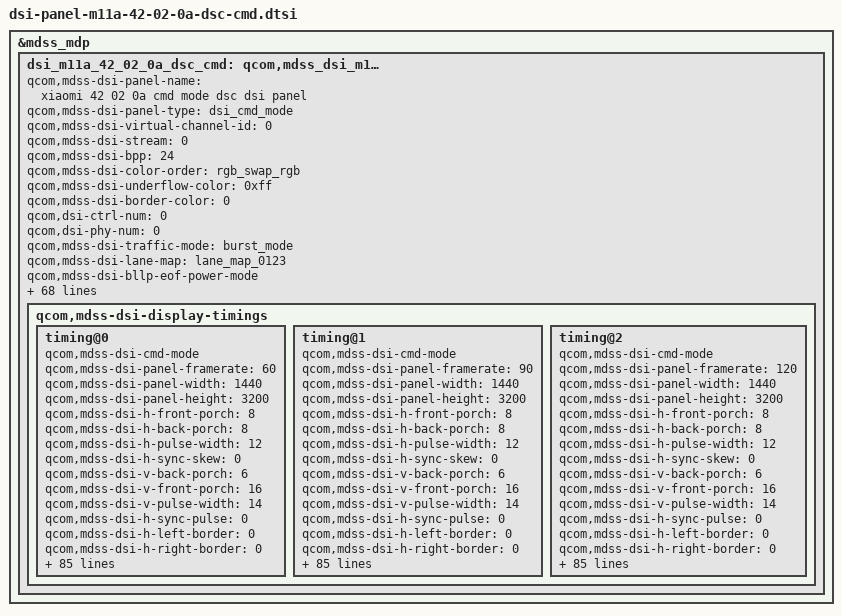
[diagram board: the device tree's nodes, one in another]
&mdss_mdp {
	dsi_m11a_42_02_0a_dsc_cmd: qcom,mdss_dsi_m11a_42_02_0a_dsc_cmd {
		qcom,mdss-dsi-panel-name = "xiaomi 42 02 0a cmd mode dsc dsi panel";
		qcom,mdss-dsi-panel-type = "dsi_cmd_mode";
		qcom,mdss-dsi-virtual-channel-id = <0>;
		qcom,mdss-dsi-stream = <0>;
		qcom,mdss-dsi-bpp = <24>;
		qcom,mdss-dsi-color-order = "rgb_swap_rgb";
		qcom,mdss-dsi-underflow-color = <0xff>;
		qcom,mdss-dsi-border-color = <0>;
		qcom,dsi-ctrl-num = <0>;
		qcom,dsi-phy-num = <0>;

		qcom,mdss-dsi-traffic-mode = "burst_mode";
		qcom,mdss-dsi-lane-map = "lane_map_0123";
		qcom,mdss-dsi-bllp-eof-power-mode;
		qcom,mdss-dsi-bllp-power-mode;
		qcom,mdss-dsi-lane-0-state;
		qcom,mdss-dsi-lane-1-state;
		qcom,mdss-dsi-lane-2-state;
		qcom,mdss-dsi-lane-3-state;
		qcom,mdss-dsi-dma-trigger = "trigger_sw";
		qcom,mdss-dsi-mdp-trigger = "none";
		qcom,mdss-dsi-reset-sequence = <1 11>, <0 1>, <1 11>;
		qcom,mdss-pan-physical-width-dimension = <701>;
		qcom,mdss-pan-physical-height-dimension = <1558>;
		qcom,mdss-dsi-te-pin-select = <1>;
		qcom,mdss-dsi-wr-mem-start = <0x2c>;
		qcom,mdss-dsi-wr-mem-continue = <0x3c>;
		qcom,mdss-dsi-te-dcs-command = <1>;
		qcom,mdss-dsi-te-check-enable;
		qcom,mdss-dsi-te-using-te-pin;
		qcom,mdss-dsi-tx-eot-append;
		qcom,mdss-dsi-lp11-init;

		qcom,mdss-dsi-bl-inverted-dbv;
		qcom,bl-update-flag = "delay_until_first_frame";

		qcom,mdss-dsi-panel-hdr-enabled;
		qcom,mdss-dsi-panel-hdr-color-primaries = <14500 15500 32000
			17000 15500 30000 8000 3000>;
		qcom,mdss-dsi-panel-peak-brightness = <4200000>;
		qcom,mdss-dsi-panel-blackness-level = <3230>;

		qcom,mdss-dsi-dma-schedule-line = <1>;
		qcom,mdss-dsi-dma-schedule-window = <50>;

		qcom,mdss-dsi-display-timings {
			/* 60 Hz */
			timing@0 {
				qcom,mdss-dsi-cmd-mode;
				qcom,mdss-dsi-panel-framerate = <60>;
				qcom,mdss-dsi-panel-width = <1440>;
				qcom,mdss-dsi-panel-height = <3200>;
				qcom,mdss-dsi-h-front-porch = <8>;
				qcom,mdss-dsi-h-back-porch = <8>;
				qcom,mdss-dsi-h-pulse-width = <12>;
				qcom,mdss-dsi-h-sync-skew = <0>;
				qcom,mdss-dsi-v-back-porch = <6>;
				qcom,mdss-dsi-v-front-porch = <16>;
				qcom,mdss-dsi-v-pulse-width = <14>;
				qcom,mdss-dsi-h-sync-pulse = <0>;
				qcom,mdss-dsi-h-left-border = <0>;
				qcom,mdss-dsi-h-right-border = <0>;
				qcom,mdss-dsi-v-top-border = <0>;
				qcom,mdss-dsi-v-bottom-border = <0>;
				qcom,mdss-dsi-panel-clockrate = <1200000000>;
				qcom,mdss-dsi-panel-jitter = <0x5 0x1>;
				qcom,mdss-mdp-transfer-time-us = <7300>;
				qcom,mdss-dsi-on-command = [
					/* swire advance 1 frame */
					39 00 00 00 00 00 06 F0 55 AA 52 08 01
					15 00 00 00 00 00 02 6F 02
					15 00 00 00 00 00 02 D2 2A
					/* DVDD strong */
					39 00 00 00 00 00 06 F0 55 AA 52 08 01
					15 00 00 00 00 00 02 6F 01
					39 00 00 00 00 00 04 C5 0B 0B 0B
					39 00 00 00 00 00 06 F0 55 AA 52 08 04
					15 00 00 00 00 00 02 C0 20
					/* Source Rising/Falling Time Strong */
					39 00 00 00 00 00 06 F0 55 AA 52 08 00
					15 00 00 00 00 00 02 6F 20
					39 00 00 00 00 00 09 C6 55 55 55 55 55 55 55 55
					39 00 00 00 00 00 05 FF AA 55 A5 80
					15 00 00 00 00 00 02 6F 1B
					15 00 00 00 00 00 02 F4 55
					15 00 00 00 00 00 02 6F 19
					15 00 00 00 00 00 02 F2 00
					39 00 00 00 00 00 05 FF AA 55 A5 81
					15 00 00 00 00 00 02 6F 18
					15 00 00 00 00 00 02 FB 04
					39 00 00 00 00 00 05 FF AA 55 A5 81
					15 00 00 00 00 00 02 6F 07
					15 00 00 00 00 00 02 FC 08
					/* CASET/RASET Setting 1440*3200 */
					39 00 00 00 00 00 05 2A 00 00 05 9F
					39 00 00 00 00 00 05 2B 00 00 0C 7F
					/* DSC Setting */
					15 00 00 00 00 00 02 90 03
					39 00 00 00 00 00 13 91
						AB A8 00 20 D2 00 02 86 03 5E 00 0A 03 5B 02 63
						10 F0
					/* TE ON */
					15 00 00 00 00 00 02 35 00
					15 00 00 00 00 00 02 5A 01
					/* Backlight On */
					39 00 00 00 00 00 05 3B 00 18 00 10
					15 00 00 00 00 00 02 53 20
					39 00 00 00 00 00 07 51 00 00 0F FF 0F FF
					15 00 00 00 00 00 02 9C 01
					15 00 00 00 00 00 02 2C 00
					/* 60Hz GIR off */
					15 00 00 00 00 00 02 2F 02
					15 00 00 40 00 00 02 5F 01
					15 00 00 40 00 00 02 26 00
					15 00 00 40 00 00 02 8B 00
					39 00 00 40 00 00 06 F0 55 AA 52 08 00
					15 00 00 40 00 00 02 6F 03
					15 00 00 40 00 00 02 C0 10
					15 00 00 40 00 00 02 6F 31
					15 00 00 40 00 00 02 DF 21
					39 00 00 40 00 00 06 F0 55 AA 52 08 02
					15 00 00 40 00 00 02 CC 30
					15 00 00 40 14 00 02 CE 01
					15 00 00 00 00 00 02 CC 00
					/* ESD Error Flag, Normal High, Error Low */
					39 00 00 40 00 00 06 F0 55 AA 52 08 00
					15 00 00 40 00 00 02 6F 05
					15 00 00 00 00 00 02 BE 88
					/* dimming step timing */
					39 00 00 40 00 00 06 F0 55 AA 52 08 00
					15 00 00 40 00 00 02 B2 09
					15 00 00 40 00 00 02 6F 05
					39 00 00 00 00 00 03 B2 08 08
					/* round on */
					39 00 00 00 00 00 06 F0 55 AA 52 08 07
					15 00 00 00 00 00 02 C0 B1
					/* Sleep Out */
					05 00 00 00 78 00 02 11 00
					/* Display On */
					05 00 00 00 00 00 02 29 00
				];
				qcom,mdss-dsi-off-command = [
					39 00 00 00 14 00 02 28 00
					39 00 00 00 64 00 02 10 00
				];
				qcom,mdss-dsi-on-command-state = "dsi_lp_mode";
				qcom,mdss-dsi-off-command-state = "dsi_lp_mode";

				qcom,mdss-dsi-timing-switch-command = [
					/* 60Hz */
					15 00 00 00 00 00 02 2F 02
					15 00 00 40 00 00 02 8B 00
					39 00 00 40 00 00 06 F0 55 AA 52 08 00
					15 00 00 40 00 00 02 6F 03
					15 00 00 40 00 00 02 C0 10
					15 00 00 40 00 00 02 6F 31
					15 00 00 40 00 00 02 DF 21
					39 00 00 40 00 00 06 F0 55 AA 52 08 02
					15 00 00 40 00 00 02 CC 30
					15 00 00 00 14 00 02 CE 01
					15 00 00 00 00 00 02 CC 00
				];

				qcom,mdss-dsi-timing-switch-command-update = <0xC0 4 1>, <0xDF 6 1>;
				qcom,mdss-dsi-timing-switch-command-state = "dsi_hs_mode";

				qcom,mdss-dsi-nolp-command = [
					39 00 00 40 00 00 03 51 00 00
					39 00 00 40 00 00 06 F0 55 AA 52 08 01
					15 00 00 40 00 00 02 6F 02
					15 00 00 40 00 00 02 B0 08
					15 00 00 40 00 00 02 E4 80
					15 00 00 40 00 00 02 6F 0A
					15 00 00 40 00 00 02 E4 80
					15 00 00 40 00 00 02 65 00
					05 00 00 00 00 00 01 38
					/* restore 60hz GIR off*/
					15 00 00 40 00 00 02 2F 02
					15 00 00 40 00 00 02 5F 01
					15 00 00 40 00 00 02 26 00
					15 00 00 40 00 00 02 8B 00
					39 00 00 40 00 00 06 F0 55 AA 52 08 00
					15 00 00 40 00 00 02 6F 03
					15 00 00 40 00 00 02 C0 10
					15 00 00 40 00 00 02 6F 31
					15 00 00 40 00 00 02 DF 20
					39 00 00 40 00 00 06 F0 55 AA 52 08 02
					15 00 00 40 00 00 02 CC 30
					15 00 00 00 14 00 02 CE 01
					15 00 00 00 00 00 02 CC 00
				];
				qcom,mdss-dsi-nolp-command-state = "dsi_hs_mode";

				qcom,compression-mode = "dsc";
				qcom,mdss-dsc-version = <0x12>;
				qcom,mdss-dsc-scr-version = <0x0>;
				qcom,mdss-dsc-slice-height = <32>;
				qcom,mdss-dsc-slice-width = <720>;
				qcom,mdss-dsc-slice-per-pkt = <2>;
				qcom,mdss-dsc-bit-per-component = <10>;
				qcom,mdss-dsc-bit-per-pixel = <8>;
				qcom,mdss-dsc-block-prediction-enable;
			};

			/* 90 Hz */
			timing@1 {
				qcom,mdss-dsi-cmd-mode;
				qcom,mdss-dsi-panel-framerate = <90>;
				qcom,mdss-dsi-panel-width = <1440>;
				qcom,mdss-dsi-panel-height = <3200>;
				qcom,mdss-dsi-h-front-porch = <8>;
				qcom,mdss-dsi-h-back-porch = <8>;
				qcom,mdss-dsi-h-pulse-width = <12>;
				qcom,mdss-dsi-h-sync-skew = <0>;
				qcom,mdss-dsi-v-back-porch = <6>;
				qcom,mdss-dsi-v-front-porch = <16>;
				qcom,mdss-dsi-v-pulse-width = <14>;
				qcom,mdss-dsi-h-sync-pulse = <0>;
				qcom,mdss-dsi-h-left-border = <0>;
				qcom,mdss-dsi-h-right-border = <0>;
				qcom,mdss-dsi-v-top-border = <0>;
				qcom,mdss-dsi-v-bottom-border = <0>;
				qcom,mdss-dsi-panel-clockrate = <1200000000>;
				qcom,mdss-dsi-panel-jitter = <0x5 0x1>;
				qcom,mdss-mdp-transfer-time-us = <7300>;
				qcom,mdss-dsi-on-command = [
					/* swire advance 1 frame */
					39 00 00 00 00 00 06 F0 55 AA 52 08 01
					15 00 00 00 00 00 02 6F 02
					15 00 00 00 00 00 02 D2 2A
					/* DVDD strong */
					39 00 00 00 00 00 06 F0 55 AA 52 08 01
					15 00 00 00 00 00 02 6F 01
					39 00 00 00 00 00 04 C5 0B 0B 0B
					39 00 00 00 00 00 06 F0 55 AA 52 08 04
					15 00 00 00 00 00 02 C0 20
					/* Source Rising/Falling Time Strong */
					39 00 00 00 00 00 06 F0 55 AA 52 08 00
					15 00 00 00 00 00 02 6F 20
					39 00 00 00 00 00 09 C6 55 55 55 55 55 55 55 55
					39 00 00 00 00 00 05 FF AA 55 A5 80
					15 00 00 00 00 00 02 6F 1B
					15 00 00 00 00 00 02 F4 55
					15 00 00 00 00 00 02 6F 19
					15 00 00 00 00 00 02 F2 00
					39 00 00 00 00 00 05 FF AA 55 A5 81
					15 00 00 00 00 00 02 6F 18
					15 00 00 00 00 00 02 FB 04
					39 00 00 00 00 00 05 FF AA 55 A5 81
					15 00 00 00 00 00 02 6F 07
					15 00 00 00 00 00 02 FC 08
					/* CASET/RASET Setting 1440*3200 */
					39 00 00 00 00 00 05 2A 00 00 05 9F
					39 00 00 00 00 00 05 2B 00 00 0C 7F
					/* DSC Setting */
					15 00 00 00 00 00 02 90 03
					39 00 00 00 00 00 13 91
						AB A8 00 20 D2 00 02 86 03 5E 00 0A 03 5B 02 63
						10 F0
					/* TE ON */
					15 00 00 00 00 00 02 35 00
					15 00 00 00 00 00 02 5A 01
					/* Backlight On */
					39 00 00 00 00 00 05 3B 00 18 00 10
					15 00 00 00 00 00 02 53 20
					39 00 00 00 00 00 07 51 00 00 0F FF 0F FF
					15 00 00 00 00 00 02 9C 01
					15 00 00 00 00 00 02 2C 00
					/* 90Hz GIR off */
					15 00 00 00 00 00 02 2F 01
					15 00 00 40 00 02 5F 01
					15 00 00 40 00 00 02 26 00
					15 00 00 40 00 00 02 8B 10
					39 00 00 40 00 00 06 F0 55 AA 52 08 00
					15 00 00 40 00 00 02 6F 03
					15 00 00 40 00 00 02 C0 10
					15 00 00 40 00 00 02 6F 31
					15 00 00 40 00 00 02 DF 20
					39 00 00 40 00 00 06 F0 55 AA 52 08 02
					15 00 00 40 00 00 02 CC 30
					15 00 00 40 14 00 02 CE 01
					15 00 00 00 00 00 02 CC 00
					/* ESD Error Flag, Normal High, Error Low */
					39 00 00 40 00 00 06 F0 55 AA 52 08 00
					15 00 00 40 00 00 02 6F 05
					15 00 00 00 00 00 02 BE 88
					/* dimming step timing */
					39 00 00 40 00 00 06 F0 55 AA 52 08 00
					15 00 00 40 00 00 02 B2 09
					15 00 00 40 00 00 02 6F 05
					39 00 00 00 00 00 03 B2 08 08
					/* round on */
					39 00 00 00 00 00 06 F0 55 AA 52 08 07
					15 00 00 00 00 00 02 C0 B1
					/* Sleep Out */
					05 00 00 00 78 00 02 11 00
					/* Display On */
					05 00 00 00 00 00 02 29 00
				];
				qcom,mdss-dsi-off-command = [
					39 00 00 00 14 00 02 28 00
					39 00 00 00 64 00 02 10 00
				];
				qcom,mdss-dsi-on-command-state = "dsi_lp_mode";
				qcom,mdss-dsi-off-command-state = "dsi_lp_mode";

				qcom,mdss-dsi-timing-switch-command = [
					/* 90hz */
					15 00 00 00 00 00 02 2F 01
					15 00 00 40 00 00 02 8B 10
					39 00 00 40 00 00 06 F0 55 AA 52 08 00
					15 00 00 40 00 00 02 6F 03
					15 00 00 40 00 00 02 C0 10
					15 00 00 40 00 00 02 6F 31
					15 00 00 40 00 00 02 DF 20
					39 00 00 40 00 00 06 F0 55 AA 52 08 02
					15 00 00 40 00 00 02 CC 30
					15 00 00 00 0D 00 02 CE 01
					15 00 00 00 00 00 02 CC 00
				];

				qcom,mdss-dsi-timing-switch-command-update = <0xC0 4 1>, <0xDF 6 1>;
				qcom,mdss-dsi-timing-switch-command-state = "dsi_hs_mode";

				qcom,mdss-dsi-nolp-command = [
					39 00 00 40 00 00 03 51 00 00
					39 00 00 40 00 00 06 F0 55 AA 52 08 01
					15 00 00 40 00 00 02 6F 02
					15 00 00 40 00 00 02 B0 08
					15 00 00 40 00 00 02 E4 80
					15 00 00 40 00 00 02 6F 0A
					15 00 00 40 00 00 02 E4 80
					15 00 00 40 00 00 02 65 00
					05 00 00 00 00 00 01 38
					/* restore 90hz GIR off */
					15 00 00 40 00 00 02 2F 01
					15 00 00 40 00 00 02 5F 01
					15 00 00 40 00 00 02 26 00
					15 00 00 40 00 00 02 8B 00
					39 00 00 40 00 00 06 F0 55 AA 52 08 00
					15 00 00 40 00 00 02 6F 03
					15 00 00 40 00 00 02 C0 10
					15 00 00 40 00 00 02 6F 31
					15 00 00 40 00 00 02 DF 20
					39 00 00 40 00 00 06 F0 55 AA 52 08 02
					15 00 00 40 00 00 02 CC 30
					15 00 00 00 0D 00 02 CE 01
					15 00 00 00 00 00 02 CC 00
				];
				qcom,mdss-dsi-nolp-command-state = "dsi_hs_mode";

				qcom,compression-mode = "dsc";
				qcom,mdss-dsc-version = <0x12>;
				qcom,mdss-dsc-scr-version = <0x0>;
				qcom,mdss-dsc-slice-height = <32>;
				qcom,mdss-dsc-slice-width = <720>;
				qcom,mdss-dsc-slice-per-pkt = <2>;
				qcom,mdss-dsc-bit-per-component = <10>;
				qcom,mdss-dsc-bit-per-pixel = <8>;
				qcom,mdss-dsc-block-prediction-enable;
			};

			/* 120 Hz */
			timing@2 {
				qcom,mdss-dsi-cmd-mode;
				qcom,mdss-dsi-panel-framerate = <120>;
				qcom,mdss-dsi-panel-width = <1440>;
				qcom,mdss-dsi-panel-height = <3200>;
				qcom,mdss-dsi-h-front-porch = <8>;
				qcom,mdss-dsi-h-back-porch = <8>;
				qcom,mdss-dsi-h-pulse-width = <12>;
				qcom,mdss-dsi-h-sync-skew = <0>;
				qcom,mdss-dsi-v-back-porch = <6>;
				qcom,mdss-dsi-v-front-porch = <16>;
				qcom,mdss-dsi-v-pulse-width = <14>;
				qcom,mdss-dsi-h-sync-pulse = <0>;
				qcom,mdss-dsi-h-left-border = <0>;
				qcom,mdss-dsi-h-right-border = <0>;
				qcom,mdss-dsi-v-top-border = <0>;
				qcom,mdss-dsi-v-bottom-border = <0>;
				qcom,mdss-dsi-panel-clockrate = <1200000000>;
				qcom,mdss-dsi-panel-jitter = <0x5 0x1>;
				qcom,mdss-mdp-transfer-time-us = <7300>;
				qcom,mdss-dsi-on-command = [
					/* swire advance 1 frame */
					39 00 00 00 00 00 06 F0 55 AA 52 08 01
					15 00 00 00 00 00 02 6F 02
					15 00 00 00 00 00 02 D2 2A
					/* DVDD strong */
					39 00 00 00 00 00 06 F0 55 AA 52 08 01
					15 00 00 00 00 00 02 6F 01
					39 00 00 00 00 00 04 C5 0B 0B 0B
					39 00 00 00 00 00 06 F0 55 AA 52 08 04
					15 00 00 00 00 00 02 C0 20
					/* Source Rising/Falling Time Strong */
					39 00 00 00 00 00 06 F0 55 AA 52 08 00
					15 00 00 00 00 00 02 6F 20
					39 00 00 00 00 00 09 C6 55 55 55 55 55 55 55 55
					39 00 00 00 00 00 05 FF AA 55 A5 80
					15 00 00 00 00 00 02 6F 1B
					15 00 00 00 00 00 02 F4 55
					15 00 00 00 00 00 02 6F 19
					15 00 00 00 00 00 02 F2 00
					39 00 00 00 00 00 05 FF AA 55 A5 81
					15 00 00 00 00 00 02 6F 18
					15 00 00 00 00 00 02 FB 04
					39 00 00 00 00 00 05 FF AA 55 A5 81
					15 00 00 00 00 00 02 6F 07
					15 00 00 00 00 00 02 FC 08
					/* CASET/RASET Setting 1440*3200 */
					39 00 00 00 00 00 05 2A 00 00 05 9F
					39 00 00 00 00 00 05 2B 00 00 0C 7F
					/* DSC Setting */
					15 00 00 00 00 00 02 90 03
					39 00 00 00 00 00 13 91
						AB A8 00 20 D2 00 02 86 03 5E 00 0A 03 5B 02 63
						10 F0
					/* TE ON */
					15 00 00 00 00 00 02 35 00
					15 00 00 00 00 00 02 5A 01
					/* Backlight On */
					39 00 00 00 00 00 05 3B 00 18 00 10
					15 00 00 00 00 00 02 53 20
					39 00 00 00 00 00 07 51 00 00 0F FF 0F FF
					15 00 00 00 00 00 02 9C 01
					15 00 00 00 00 00 02 2C 00
					/* 120Hz GIR off*/
					15 00 00 00 00 00 02 2F 00
					15 00 00 40 00 00 02 5F 01
					15 00 00 40 00 00 02 26 00
					15 00 00 40 00 00 02 8B 00
					39 00 00 40 00 00 06 F0 55 AA 52 08 00
					15 00 00 40 00 00 02 6F 03
					15 00 00 40 00 00 02 C0 10
					15 00 00 40 00 00 02 6F 31
					15 00 00 40 00 00 02 DF 20
					39 00 00 40 00 00 06 F0 55 AA 52 08 02
					15 00 00 40 00 00 02 CC 30
					15 00 00 40 14 00 02 CE 01
					15 00 00 00 00 00 02 CC 00
					/* ESD Error Flag, Normal High, Error Low */
					39 00 00 40 00 00 06 F0 55 AA 52 08 00
					15 00 00 40 00 00 02 6F 05
					15 00 00 00 00 00 02 BE 88
					/* dimming step timing */
					39 00 00 40 00 00 06 F0 55 AA 52 08 00
					15 00 00 40 00 00 02 B2 09
					15 00 00 40 00 00 02 6F 05
					39 00 00 00 00 00 03 B2 08 08
					/* round on */
					39 00 00 00 00 00 06 F0 55 AA 52 08 07
					15 00 00 00 00 00 02 C0 B1
					/* Sleep Out */
					05 00 00 00 78 00 02 11 00
					/* Display On */
					05 00 00 00 00 00 02 29 00
				];
				qcom,mdss-dsi-off-command = [
					39 00 00 00 14 00 02 28 00
					39 00 00 00 64 00 02 10 00
				];
				qcom,mdss-dsi-on-command-state = "dsi_lp_mode";
				qcom,mdss-dsi-off-command-state = "dsi_lp_mode";

				qcom,mdss-dsi-timing-switch-command = [
					/* 120Hz */
					15 00 00 00 00 00 02 2F 00
					15 00 00 40 00 00 02 8B 00
					39 00 00 40 00 00 06 F0 55 AA 52 08 00
					15 00 00 40 00 00 02 6F 03
					15 00 00 40 00 00 02 C0 10
					15 00 00 40 00 00 02 6F 31
					15 00 00 40 00 00 02 DF 20
					39 00 00 40 00 00 06 F0 55 AA 52 08 02
					15 00 00 40 00 00 02 CC 30
					15 00 00 00 0A 00 02 CE 01
					15 00 00 00 00 00 02 CC 00
				];

				qcom,mdss-dsi-timing-switch-command-update = <0xC0 4 1>, <0xDF 6 1>;
				qcom,mdss-dsi-timing-switch-command-state = "dsi_hs_mode";

				qcom,mdss-dsi-nolp-command = [
					39 00 00 40 00 00 03 51 00 00
					39 00 00 40 00 00 06 F0 55 AA 52 08 01
					15 00 00 40 00 00 02 6F 02
					15 00 00 40 00 00 02 B0 08
					15 00 00 40 00 00 02 E4 80
					15 00 00 40 00 00 02 6F 0A
					15 00 00 40 00 00 02 E4 80
					15 00 00 40 00 00 02 65 00
					05 00 00 00 00 00 01 38
				];
				qcom,mdss-dsi-nolp-command-state = "dsi_hs_mode";

				qcom,compression-mode = "dsc";
				qcom,mdss-dsc-version = <0x12>;
				qcom,mdss-dsc-scr-version = <0x0>;
				qcom,mdss-dsc-slice-height = <32>;
				qcom,mdss-dsc-slice-width = <720>;
				qcom,mdss-dsc-slice-per-pkt = <2>;
				qcom,mdss-dsc-bit-per-component = <10>;
				qcom,mdss-dsc-bit-per-pixel = <8>;
				qcom,mdss-dsc-block-prediction-enable;
			};
		};
	};
};

&dsi_m11a_42_02_0a_dsc_cmd {
	/* IRQF_ONESHOT | IRQF_TRIGGER_LOW */
	mi,esd-err-irq-gpio = <&tlmm 116 0x2008>;

	mi,panel-id = <0x4D313141 0x00420200>;

	mi,max-brightness-clone = <16383>;
	mi,normal-max-brightness-clone = <8191>;
	mi,mdss-dsi-fac-bl-max-level = <2047>;
	mi,mdss-fac-brightness-max-level = <2047>;
	mi,hbm-bl-min-level = <1>;
	mi,hbm-bl-max-level = <2047>;

	mi,ddic-round-corner-enabled;

	mi,flat-update-flag;
	mi,flat-need-sync-te;
	mi,flat-need-update-several-gamma;

	mi,panel-build-id-read-needed;
	mi,panel-build-id-read-length = <1>;
	mi,mdss-dsi-panel-build-id-read-command = [06 01 00 01 00 00 01 DA];
	mi,mdss-dsi-panel-build-id-read-command-state = "dsi_lp_mode";

	mi,flatmode-status-check-enabled;
	mi,mdss-dsi-panel-flatmode-status-read-command = [06 01 00 01 00 00 01 5F];
	mi,mdss-dsi-panel-flatmode-status-read-command-state = "dsi_lp_mode";
	mi,mdss-dsi-panel-flatmode-status-read-length = <1>;
	mi,mdss-dsi-panel-flatmode-on-status-value = <0x00>;

	mi,local-hbm-enabled;
	mi,local-hbm-white-1000nit-update-flag;
	mi,local-hbm-white-110nit-update-flag;
	mi,local-hbm-alpha-ctrl-aa-area;
	mi,local-hbm-ctrl-df-reg;
	mi,local-hbm-ui-ready-delay-num-frame = <4>; /* 4 frame */
	mi,fod-low-brightness-clone-threshold = <200>;
	mi,fod-low-brightness-lux-threshold = <3>;

	mi,doze-hbm-dbv-level = <252>;
	mi,doze-lbm-dbv-level = <20>;

	mi,thermal-dimming-flag;
	mi,panel-on-dimming-delay = <120>;
	mi,dimming-need-update-speed;
	mi,dimming-node = <0 200 450 800 4095>;

	qcom,mdss-dsi-display-timings {
		/* 60hz */
		timing@0 {
			/* <flat on gamma, flat off gamma> */
			mi,mdss-flat-status-control-gamma-cfg = <0x32 0x10>;
			mi,mdss-flat-status-control-lhbm-gamma-cfg = <0x23 0x21>;

			mi,mdss-dsi-flat-mode-on-command = [
				15 00 00 00 00 00 02 2F 02
				15 00 00 40 00 00 02 5F 00
				15 00 00 40 00 00 02 26 02
				15 00 00 40 00 00 02 8B 00
				39 00 00 40 00 00 06 F0 55 AA 52 08 00
				15 00 00 40 00 00 02 6F 03
				15 00 00 40 00 00 02 C0 32
				15 00 00 40 00 00 02 6F 31
				15 00 00 40 00 00 02 DF 23
				39 00 00 40 00 00 06 F0 55 AA 52 08 02
				15 00 00 40 00 00 02 CC 30
				15 00 00 00 14 00 02 CE 01
			];
			mi,mdss-dsi-flat-mode-on-command-state = "dsi_lp_mode";

			mi,mdss-dsi-flat-mode-on-sec-command = [
				39 00 00 40 00 00 06 F0 55 AA 52 08 02
				15 00 00 00 00 00 02 CC 00
			];
			mi,mdss-dsi-flat-mode-on-sec-command-state = "dsi_lp_mode";

			mi,mdss-dsi-flat-mode-off-command = [
				15 00 00 00 00 00 02 2F 02
				15 00 00 40 00 00 02 5F 01
				15 00 00 40 00 00 02 26 00
				15 00 00 40 00 00 02 8B 00
				39 00 00 40 00 00 06 F0 55 AA 52 08 00
				15 00 00 40 00 00 02 6F 03
				15 00 00 40 00 00 02 C0 10
				15 00 00 40 00 00 02 6F 31
				15 00 00 40 00 00 02 DF 21
				39 00 00 40 00 00 06 F0 55 AA 52 08 02
				15 00 00 40 00 00 02 CC 30
				15 00 00 00 14 00 02 CE 01
			];
			mi,mdss-dsi-flat-mode-off-command-state = "dsi_lp_mode";

			mi,mdss-dsi-flat-mode-off-sec-command = [
				39 00 00 40 00 00 06 F0 55 AA 52 08 02
				15 00 00 00 00 00 02 CC 00
			];
			mi,mdss-dsi-flat-mode-off-sec-command-state = "dsi_lp_mode";

			mi,mdss-dsi-doze-hbm-command = [
				/* Enter 120Hz GIR off */
				15 00 00 40 00 00 02 2F 00
				15 00 00 40 00 00 02 5F 01
				15 00 00 40 00 00 02 26 00
				15 00 00 40 00 00 02 8B 00
				39 00 00 40 00 00 06 F0 55 AA 52 08 00
				15 00 00 40 00 00 02 6F 03
				15 00 00 40 00 00 02 C0 10
				15 00 00 40 00 00 02 6F 31
				15 00 00 40 00 00 02 DF 20
				39 00 00 40 00 00 06 F0 55 AA 52 08 02
				15 00 00 40 00 00 02 CC 30
				15 00 00 00 0A 00 02 CE 01
				15 00 00 00 00 00 02 CC 00
				/*  Aod Mode  -- 60nit  */
				39 00 00 40 00 00 07 51 00 00 00 00 0F FF
				39 00 00 40 00 00 06 F0 55 AA 52 08 01
				15 00 00 40 00 00 02 6F 02
				15 00 00 40 00 00 02 B0 00
				15 00 00 40 00 00 02 E4 90
				15 00 00 40 00 00 02 6F 0A
				15 00 00 40 00 00 02 E4 90
				05 00 00 40 00 00 01 39
				15 00 00 00 00 00 02 65 01
			];
			mi,mdss-dsi-doze-hbm-command-state = "dsi_hs_mode";

			mi,mdss-dsi-doze-lbm-command = [
				/* Enter 120Hz GIR off */
				15 00 00 40 00 00 02 2F 00
				15 00 00 40 00 00 02 5F 01
				15 00 00 40 00 00 02 26 00
				15 00 00 40 00 00 02 8B 00
				39 00 00 40 00 00 06 F0 55 AA 52 08 00
				15 00 00 40 00 00 02 6F 03
				15 00 00 40 00 00 02 C0 10
				15 00 00 40 00 00 02 6F 31
				15 00 00 40 00 00 02 DF 20
				39 00 00 40 00 00 06 F0 55 AA 52 08 02
				15 00 00 40 00 00 02 CC 30
				15 00 00 00 0A 00 02 CE 01
				15 00 00 00 00 00 02 CC 00
				/*  Aod Mode  -- 5nit  */
				39 00 00 40 00 00 07 51 00 00 00 00 01 55
				39 00 00 40 00 00 06 F0 55 AA 52 08 01
				15 00 00 40 00 00 02 6F 02
				15 00 00 40 00 00 02 B0 00
				15 00 00 40 00 00 02 E4 90
				15 00 00 40 00 00 02 6F 0A
				15 00 00 40 00 00 02 E4 90
				05 00 00 40 00 00 01 39
				15 00 00 00 00 00 02 65 01
			];
			mi,mdss-dsi-doze-lbm-command-state = "dsi_hs_mode";

			mi,mdss-dsi-doze-hbm-nolp-command = [
				39 00 00 40 00 00 06 F0 55 AA 52 08 01
				15 00 00 40 00 00 02 6F 02
				15 00 00 40 00 00 02 B0 08
				15 00 00 40 00 00 02 E4 80
				15 00 00 40 00 00 02 6F 0A
				15 00 00 40 00 00 02 E4 80
				15 00 00 40 00 00 02 65 00
				05 00 00 00 32 00 01 38
				/* restore 60hz GIR off */
				15 00 00 40 00 00 02 2F 02
				15 00 00 40 00 00 02 5F 01
				15 00 00 40 00 00 02 26 00
				15 00 00 40 00 00 02 8B 00
				39 00 00 40 00 00 06 F0 55 AA 52 08 00
				15 00 00 40 00 00 02 6F 03
				15 00 00 40 00 00 02 C0 10
				15 00 00 40 00 00 02 6F 31
				15 00 00 40 00 00 02 DF 21
				39 00 00 40 00 00 06 F0 55 AA 52 08 02
				15 00 00 40 00 00 02 CC 30
				15 00 00 00 14 00 02 CE 01
				15 00 00 00 00 00 02 CC 00
			];
			mi,mdss-dsi-doze-hbm-nolp-command-state = "dsi_hs_mode";

			mi,mdss-dsi-doze-lbm-nolp-command = [
				39 00 00 40 00 00 06 F0 55 AA 52 08 01
				15 00 00 40 00 00 02 6F 02
				15 00 00 40 00 00 02 B0 08
				15 00 00 40 00 00 02 E4 80
				15 00 00 40 00 00 02 6F 0A
				15 00 00 40 00 00 02 E4 80
				15 00 00 40 00 00 02 65 00
				05 00 00 00 32 00 01 38
				/* restore 60hz GIR off */
				15 00 00 40 00 00 02 2F 02
				15 00 00 40 00 00 02 5F 01
				15 00 00 40 00 00 02 26 00
				15 00 00 40 00 00 02 8B 00
				39 00 00 40 00 00 06 F0 55 AA 52 08 00
				15 00 00 40 00 00 02 6F 03
				15 00 00 40 00 00 02 C0 10
				15 00 00 40 00 00 02 6F 31
				15 00 00 40 00 00 02 DF 21
				39 00 00 40 00 00 06 F0 55 AA 52 08 02
				15 00 00 40 00 00 02 CC 30
				15 00 00 00 14 00 02 CE 01
				15 00 00 00 00 00 02 CC 00
			];
			mi,mdss-dsi-doze-lbm-nolp-command-state = "dsi_hs_mode";

			mi,mdss-dsi-local-hbm-off-to-hlpm-command = [
				/* Lhbm off */
				39 00 00 40 00 00 03 51 07 FF
				39 00 00 40 00 00 02 86 00
				39 00 00 00 00 00 02 87 20
				/* Enter 120Hz GIR off */
				15 00 00 40 00 00 02 2F 00
				15 00 00 40 00 00 02 5F 01
				15 00 00 40 00 00 02 26 00
				15 00 00 40 00 00 02 8B 00
				39 00 00 40 00 00 06 F0 55 AA 52 08 00
				15 00 00 40 00 00 02 6F 03
				15 00 00 40 00 00 02 C0 10
				15 00 00 40 00 00 02 6F 31
				15 00 00 40 00 00 02 DF 20
				39 00 00 40 00 00 06 F0 55 AA 52 08 02
				15 00 00 40 00 00 02 CC 30
				15 00 00 00 0A 00 02 CE 01
				15 00 00 00 00 00 02 CC 00
				/* Aod hlpm */
				39 00 00 40 00 00 07 51 00 00 00 00 0F FF
				39 00 00 40 00 00 06 F0 55 AA 52 08 01
				39 00 00 40 00 00 02 6F 02
				39 00 00 40 00 00 02 B0 00
				39 00 00 40 00 00 02 E4 90
				39 00 00 40 00 00 02 6F 0A
				39 00 00 40 00 00 02 E4 90
				39 00 00 40 00 00 02 39 00
				39 00 00 00 00 00 02 65 01
			];
			mi,mdss-dsi-local-hbm-off-to-hlpm-command-state = "dsi_hs_mode";

			mi,mdss-dsi-local-hbm-off-to-llpm-command = [
				/* Lhbm off */
				39 00 00 40 00 00 03 51 07 FF
				39 00 00 40 00 00 02 86 00
				39 00 00 00 00 00 02 87 20
				/* Enter 120Hz GIR off */
				15 00 00 40 00 00 02 2F 00
				15 00 00 40 00 00 02 5F 01
				15 00 00 40 00 00 02 26 00
				15 00 00 40 00 00 02 8B 00
				39 00 00 40 00 00 06 F0 55 AA 52 08 00
				15 00 00 40 00 00 02 6F 03
				15 00 00 40 00 00 02 C0 10
				15 00 00 40 00 00 02 6F 31
				15 00 00 40 00 00 02 DF 20
				39 00 00 40 00 00 06 F0 55 AA 52 08 02
				15 00 00 40 00 00 02 CC 30
				15 00 00 00 0A 00 02 CE 01
				15 00 00 00 00 00 02 CC 00
				/* Aod llpm */
				39 00 00 40 00 00 07 51 00 00 00 00 01 55
				39 00 00 40 00 00 06 F0 55 AA 52 08 01
				39 00 00 40 00 00 02 6F 02
				39 00 00 40 00 00 02 B0 00
				39 00 00 40 00 00 02 E4 90
				39 00 00 40 00 00 02 6F 0A
				39 00 00 40 00 00 02 E4 90
				39 00 00 40 00 00 02 39 00
				39 00 00 00 00 00 02 65 01
			];
			mi,mdss-dsi-local-hbm-off-to-llpm-command-state = "dsi_hs_mode";

			mi,mdss-dsi-local-hbm-hlpm-white-1000nit-command = [
				/* Aod off */
				39 00 00 40 00 00 03 51 00 00
				39 00 00 40 00 00 06 F0 55 AA 52 08 01
				15 00 00 40 00 00 02 6F 02
				15 00 00 40 00 00 02 B0 08
				15 00 00 40 00 00 02 E4 80
				15 00 00 40 00 00 02 6F 0A
				15 00 00 40 00 00 02 E4 80
				15 00 00 40 00 00 02 65 00
				15 00 00 00 00 00 02 38 00
				/* restore 60hz GIR off */
				15 00 00 40 00 00 02 2F 02
				15 00 00 40 00 00 02 5F 01
				15 00 00 40 00 00 02 26 00
				15 00 00 40 00 00 02 8B 00
				39 00 00 40 00 00 06 F0 55 AA 52 08 00
				15 00 00 40 00 00 02 6F 03
				15 00 00 40 00 00 02 C0 10
				15 00 00 40 00 00 02 6F 31
				15 00 00 40 00 00 02 DF 21
				39 00 00 40 00 00 06 F0 55 AA 52 08 02
				15 00 00 40 00 00 02 CC 30
				15 00 00 00 14 00 02 CE 01
				15 00 00 00 00 00 02 CC 00
				/* RND Setting for LHBM */
				39 00 00 40 00 00 06 F0 55 AA 52 08 07
				15 00 00 40 00 00 02 C0 B1
				/* local hbm setting */
				39 00 00 40 00 00 06 F0 55 AA 52 08 00
				39 00 00 40 00 00 04 DF 45 00 00
				15 00 00 40 00 00 02 6F 13
				39 00 00 40 00 00 05 DF 02 D0 0B 42
				15 00 00 40 00 00 02 6F 1B
				39 00 00 40 00 00 05 DF 02 54 0A C6
				15 00 00 40 00 00 02 6F 1F
				39 00 00 40 00 00 05 DF 03 4C 0B BE
				15 00 00 40 00 00 02 6F 2B
				39 00 00 40 00 00 07 DF 3F FF 3F FF 3F FF
				15 00 00 40 00 00 02 6F 32
				39 00 00 40 00 00 07 DF 00 00 13 00 00 00
				/* EM_DT_FP-14 bit */
				15 00 00 40 00 00 02 6F 38
				39 00 00 40 00 00 03 DF 00 40
				15 00 00 40 00 00 02 6F 88
				15 00 00 40 00 00 02 DF 40
				/* FPR1_EN FPR1_CENTER_X/Y */
				15 00 00 40 00 00 02 6F 00
				39 00 00 40 00 00 06 88 01 02 D0 0B 44
				/* Dimming */
				15 00 00 40 00 00 02 53 20
				/* DBV_DIM_FP - 14 bit */
				39 00 00 40 00 00 06 F0 55 AA 52 08 00
				15 00 00 40 00 00 02 6F 4C
				39 00 00 40 00 00 03 DF 05 1C
				/* FPR Gamma code, R/G/B[11:0] */
				39 00 00 40 00 00 06 F0 55 AA 52 08 02
				39 00 00 40 00 00 07 D0 0B 06 09 97 0B 69
				/* FPR ALPHA */
				15 00 00 40 00 00 02 6F 01
				39 00 00 40 00 00 03 87 0D FF
				/* FPR ON */
				15 00 00 40 00 00 02 87 21
				15 00 00 00 00 00 02 85 00
			];
			mi,mdss-dsi-local-hbm-hlpm-white-1000nit-command-update = <0x87 49 2>, <0xD0 47 6>, <0xDF 45 2>;
			mi,mdss-dsi-local-hbm-hlpm-white-1000nit-command-state = "dsi_hs_mode";

			mi,mdss-dsi-local-hbm-hlpm-white-110nit-command = [
				/* AOD off */
				39 00 00 40 00 00 03 51 00 00
				39 00 00 40 00 00 06 F0 55 AA 52 08 01
				15 00 00 40 00 00 02 6F 02
				15 00 00 40 00 00 02 B0 08
				15 00 00 40 00 00 02 E4 80
				15 00 00 40 00 00 02 6F 0A
				15 00 00 40 00 00 02 E4 80
				15 00 00 40 00 00 02 65 00
				15 00 00 00 00 00 02 38 00
				/* restore 60hz */
				15 00 00 40 00 00 02 2F 02
				15 00 00 40 00 00 02 5F 01
				15 00 00 40 00 00 02 26 00
				15 00 00 40 00 00 02 8B 00
				39 00 00 40 00 00 06 F0 55 AA 52 08 00
				15 00 00 40 00 00 02 6F 03
				15 00 00 40 00 00 02 C0 10
				15 00 00 40 00 00 02 6F 31
				15 00 00 40 00 00 02 DF 21
				39 00 00 40 00 00 06 F0 55 AA 52 08 02
				15 00 00 40 00 00 02 CC 30
				15 00 00 00 14 00 02 CE 01
				15 00 00 00 00 00 02 CC 00
				/* RND Setting for LHBM */
				39 00 00 40 00 00 06 F0 55 AA 52 08 07
				15 00 00 40 00 00 02 C0 B1
				/* local hbm setting */
				39 00 00 40 00 00 06 F0 55 AA 52 08 00
				39 00 00 40 00 00 04 DF 45 00 00
				15 00 00 40 00 00 02 6F 13
				39 00 00 40 00 00 05 DF 02 D0 0B 42
				15 00 00 40 00 00 02 6F 1B
				39 00 00 40 00 00 05 DF 02 54 0A C6
				15 00 00 40 00 00 02 6F 1F
				39 00 00 40 00 00 05 DF 03 4C 0B BE
				15 00 00 40 00 00 02 6F 2B
				39 00 00 40 00 00 07 DF 3F FF 3F FF 3F FF
				15 00 00 40 00 00 02 6F 32
				39 00 00 40 00 00 07 DF 00 00 13 00 00 00
				/* EM_DT_FP-14 bit */
				15 00 00 40 00 00 02 6F 38
				39 00 00 40 00 00 03 DF 00 40
				15 00 00 40 00 00 02 6F 88
				15 00 00 40 00 00 02 DF 40
				/* FPR1_EN FPR1_CENTER_X/Y */
				15 00 00 40 00 00 02 6F 00
				39 00 00 40 00 00 06 88 01 02 D0 0B 44
				/* Dimming */
				15 00 00 40 00 00 02 53 20
				/* DBV_DIM_FP - 14 bit */
				39 00 00 40 00 00 06 F0 55 AA 52 08 00
				15 00 00 40 00 00 02 6F 4C
				39 00 00 40 00 00 03 DF 05 1C
				/* FPR Gamma code, R/G/B[11:0] */
				39 00 00 40 00 00 06 F0 55 AA 52 08 02
				39 00 00 40 00 00 07 D0 08 00 07 26 08 7F
				/* FPR ALPHA */
				15 00 00 40 00 00 02 6F 01
				39 00 00 40 00 00 03 87 0D FF
				/* FPR ON */
				15 00 00 40 00 00 02 87 21
				15 00 00 00 00 00 02 85 00
			];
			mi,mdss-dsi-local-hbm-hlpm-white-110nit-command-update  = <0x87 49 3>, <0xD0 47 6>;
			mi,mdss-dsi-local-hbm-hlpm-white-110nit-command-state = "dsi_hs_mode";

			#include "dsi-panel-m11a-42-02-0a-dsc-cmd-common.dtsi"
		};

		/* 90hz */
		timing@1 {
			/* <flat on gamma, flat off gamma> */
			mi,mdss-flat-status-control-gamma-cfg = <0x32 0x10>;
			mi,mdss-flat-status-control-lhbm-gamma-cfg = <0x22 0x20>;

			mi,mdss-dsi-flat-mode-on-command = [
				15 00 00 00 00 00 02 2F 01
				15 00 00 40 00 00 02 5F 00
				15 00 00 40 00 00 02 26 02
				15 00 00 40 00 00 02 8B 10
				39 00 00 40 00 00 06 F0 55 AA 52 08 00
				15 00 00 40 00 00 02 6F 03
				15 00 00 40 00 00 02 C0 32
				15 00 00 40 00 00 02 6F 31
				15 00 00 40 00 00 02 DF 22
				39 00 00 40 00 00 06 F0 55 AA 52 08 02
				15 00 00 40 00 00 02 CC 30
				15 00 00 00 14 00 02 CE 01
			];
			mi,mdss-dsi-flat-mode-on-command-state = "dsi_lp_mode";

			mi,mdss-dsi-flat-mode-on-sec-command = [
				39 00 00 40 00 00 06 F0 55 AA 52 08 02
				15 00 00 00 00 00 02 CC 00
			];
			mi,mdss-dsi-flat-mode-on-sec-command-state = "dsi_lp_mode";

			mi,mdss-dsi-flat-mode-off-command = [
				15 00 00 00 00 00 02 2F 01
				15 00 00 40 00 00 02 5F 01
				15 00 00 40 00 00 02 26 00
				15 00 00 40 00 00 02 8B 10
				39 00 00 40 00 00 06 F0 55 AA 52 08 00
				15 00 00 40 00 00 02 6F 03
				15 00 00 40 00 00 02 C0 10
				15 00 00 40 00 00 02 6F 31
				15 00 00 40 00 00 02 DF 20
				39 00 00 40 00 00 06 F0 55 AA 52 08 02
				15 00 00 40 00 00 02 CC 30
				15 00 00 00 14 00 02 CE 01
			];
			mi,mdss-dsi-flat-mode-off-command-state = "dsi_lp_mode";
			mi,mdss-dsi-flat-mode-off-sec-command = [
				39 00 00 40 00 00 06 F0 55 AA 52 08 02
				15 00 00 00 00 00 02 CC 00
			];
			mi,mdss-dsi-flat-mode-off-sec-command-state = "dsi_lp_mode";

			mi,mdss-dsi-doze-hbm-command = [
				/* Enter 120Hz GIR off */
				15 00 00 40 00 00 02 2F 00
				15 00 00 40 00 00 02 5F 01
				15 00 00 40 00 00 02 26 00
				15 00 00 40 00 00 02 8B 00
				39 00 00 40 00 00 06 F0 55 AA 52 08 00
				15 00 00 40 00 00 02 6F 03
				15 00 00 40 00 00 02 C0 10
				15 00 00 40 00 00 02 6F 31
				15 00 00 40 00 00 02 DF 20
				15 00 00 00 0A 00 02 CE 01
				15 00 00 00 00 00 02 CC 00
				/*  Aod Mode  -- 60nit  */
				39 00 00 40 00 00 07 51 00 00 00 00 0F FF
				39 00 00 40 00 00 06 F0 55 AA 52 08 01
				15 00 00 40 00 00 02 6F 02
				15 00 00 40 00 00 02 B0 00
				15 00 00 40 00 00 02 E4 90
				15 00 00 40 00 00 02 6F 0A
				15 00 00 40 00 00 02 E4 90
				05 00 00 40 00 00 01 39
				15 00 00 00 00 00 02 65 01
			];
			mi,mdss-dsi-doze-hbm-command-state = "dsi_hs_mode";

			mi,mdss-dsi-doze-lbm-command = [
				/* Enter 120Hz GIR off */
				15 00 00 40 00 00 02 2F 00
				15 00 00 40 00 00 02 5F 01
				15 00 00 40 00 00 02 26 00
				15 00 00 40 00 00 02 8B 00
				39 00 00 40 00 00 06 F0 55 AA 52 08 00
				15 00 00 40 00 00 02 6F 03
				15 00 00 40 00 00 02 C0 10
				15 00 00 40 00 00 02 6F 31
				15 00 00 40 00 00 02 DF 20
				39 00 00 40 00 00 06 F0 55 AA 52 08 02
				15 00 00 40 00 00 02 CC 30
				15 00 00 00 0A 00 02 CE 01
				15 00 00 00 00 00 02 CC 00
				/*  Aod Mode  -- 5nit  */
				39 00 00 40 00 00 07 51 00 00 00 00 01 55
				39 00 00 40 00 00 06 F0 55 AA 52 08 01
				15 00 00 40 00 00 02 6F 02
				15 00 00 40 00 00 02 B0 00
				15 00 00 40 00 00 02 E4 90
				15 00 00 40 00 00 02 6F 0A
				15 00 00 40 00 00 02 E4 90
				05 00 00 40 00 00 01 39
				15 00 00 00 00 00 02 65 01
			];
			mi,mdss-dsi-doze-lbm-command-state = "dsi_hs_mode";

			mi,mdss-dsi-doze-hbm-nolp-command = [
				/* Aod off */
				39 00 00 40 00 00 06 F0 55 AA 52 08 01
				15 00 00 40 00 00 02 6F 02
				15 00 00 40 00 00 02 B0 08
				15 00 00 40 00 00 02 E4 80
				15 00 00 40 00 00 02 6F 0A
				15 00 00 40 00 00 02 E4 80
				15 00 00 40 00 00 02 65 00
				05 00 00 00 32 00 01 38
				/* restore 90hz GIR off */
				15 00 00 40 00 00 02 2F 01
				15 00 00 40 00 00 02 5F 01
				15 00 00 40 00 00 02 26 00
				15 00 00 40 00 00 02 8B 00
				39 00 00 40 00 00 06 F0 55 AA 52 08 00
				15 00 00 40 00 00 02 6F 03
				15 00 00 40 00 00 02 C0 10
				15 00 00 40 00 00 02 6F 31
				15 00 00 40 00 00 02 DF 20
				39 00 00 40 00 00 06 F0 55 AA 52 08 02
				15 00 00 40 00 00 02 CC 30
				15 00 00 00 0D 00 02 CE 01
				15 00 00 00 00 00 02 CC 00
			];
			mi,mdss-dsi-doze-hbm-nolp-command-state = "dsi_hs_mode";

			mi,mdss-dsi-doze-lbm-nolp-command = [
				/* Aod off */
				39 00 00 40 00 00 06 F0 55 AA 52 08 01
				15 00 00 40 00 00 02 6F 02
				15 00 00 40 00 00 02 B0 08
				15 00 00 40 00 00 02 E4 80
				15 00 00 40 00 00 02 6F 0A
				15 00 00 40 00 00 02 E4 80
				15 00 00 40 00 00 02 65 00
				05 00 00 00 32 00 01 38
				/* restore 90hz GIR off */
				15 00 00 40 00 00 02 2F 01
				15 00 00 40 00 00 02 5F 01
				15 00 00 40 00 00 02 26 00
				15 00 00 40 00 00 02 8B 00
				39 00 00 40 00 00 06 F0 55 AA 52 08 00
				15 00 00 40 00 00 02 6F 03
				15 00 00 40 00 00 02 C0 10
				15 00 00 40 00 00 02 6F 31
				15 00 00 40 00 00 02 DF 20
				39 00 00 40 00 00 06 F0 55 AA 52 08 02
				15 00 00 40 00 00 02 CC 30
				15 00 00 00 0D 00 02 CE 01
				15 00 00 00 00 00 02 CC 00
			];
			mi,mdss-dsi-doze-lbm-nolp-command-state = "dsi_hs_mode";

			mi,mdss-dsi-local-hbm-off-to-hlpm-command = [
				/* Lhbm off */
				39 00 00 40 00 00 03 51 07 FF
				15 00 00 40 00 00 02 86 00
				15 00 00 00 00 00 02 87 20
				/* Enter 120Hz GIR off */
				15 00 00 40 00 00 02 2F 00
				15 00 00 40 00 00 02 5F 01
				15 00 00 40 00 00 02 26 00
				15 00 00 40 00 00 02 8B 00
				39 00 00 40 00 00 06 F0 55 AA 52 08 00
				15 00 00 40 00 00 02 6F 03
				15 00 00 40 00 00 02 C0 10
				15 00 00 40 00 00 02 6F 31
				15 00 00 40 00 00 02 DF 20
				39 00 00 40 00 00 06 F0 55 AA 52 08 02
				15 00 00 40 00 00 02 CC 30
				15 00 00 00 0A 00 02 CE 01
				15 00 00 00 00 00 02 CC 00
				/* Aod hlpm */
				39 00 00 40 00 00 07 51 00 00 00 00 0F FF
				39 00 00 40 00 00 06 F0 55 AA 52 08 01
				15 00 00 40 00 00 02 6F 02
				15 00 00 40 00 00 02 B0 00
				15 00 00 40 00 00 02 E4 90
				15 00 00 40 00 00 02 6F 0A
				15 00 00 40 00 00 02 E4 90
				15 00 00 40 00 00 02 39 00
				15 00 00 00 00 00 02 65 01
			];
			mi,mdss-dsi-local-hbm-off-to-hlpm-command-state = "dsi_hs_mode";

			mi,mdss-dsi-local-hbm-off-to-llpm-command = [
				/* Lhbm off */
				39 00 00 40 00 00 03 51 07 FF
				39 00 00 40 00 00 02 86 00
				39 00 00 00 00 00 02 87 20
				/* Enter 120Hz GIR off */
				15 00 00 40 00 00 02 2F 00
				15 00 00 40 00 00 02 5F 01
				15 00 00 40 00 00 02 26 00
				15 00 00 40 00 00 02 8B 00
				39 00 00 40 00 00 06 F0 55 AA 52 08 00
				15 00 00 40 00 00 02 6F 03
				15 00 00 40 00 00 02 C0 10
				15 00 00 40 00 00 02 6F 31
				15 00 00 40 00 00 02 DF 20
				39 00 00 40 00 00 06 F0 55 AA 52 08 02
				15 00 00 40 00 00 02 CC 30
				15 00 00 00 0A 00 02 CE 01
				15 00 00 00 00 00 02 CC 00
				/* Aod llpm */
				39 00 00 40 00 00 07 51 00 00 00 00 01 55
				39 00 00 40 00 00 06 F0 55 AA 52 08 01
				15 00 00 40 00 00 02 6F 02
				15 00 00 40 00 00 02 B0 00
				15 00 00 40 00 00 02 E4 90
				15 00 00 40 00 00 02 6F 0A
				15 00 00 40 00 00 02 E4 90
				15 00 00 40 00 00 02 39 00
				15 00 00 00 00 00 02 65 01
			];
			mi,mdss-dsi-local-hbm-off-to-llpm-command-state = "dsi_hs_mode";

			mi,mdss-dsi-local-hbm-hlpm-white-1000nit-command = [
				/* Aod off */
				39 00 00 40 00 00 03 51 00 00
				39 00 00 40 00 00 06 F0 55 AA 52 08 01
				15 00 00 40 00 00 02 6F 02
				15 00 00 40 00 00 02 B0 08
				15 00 00 40 00 00 02 E4 80
				15 00 00 40 00 00 02 6F 0A
				15 00 00 40 00 00 02 E4 80
				15 00 00 40 00 00 02 65 00
				15 00 00 00 00 00 02 38 00
				/* restore 90hz GIR off */
				15 00 00 40 00 00 02 2F 01
				15 00 00 40 00 00 02 5F 01
				15 00 00 40 00 00 02 26 00
				15 00 00 40 00 00 02 8B 00
				39 00 00 40 00 00 06 F0 55 AA 52 08 00
				15 00 00 40 00 00 02 6F 03
				15 00 00 40 00 00 02 C0 10
				15 00 00 40 00 00 02 6F 31
				15 00 00 40 00 00 02 DF 20
				39 00 00 40 00 00 06 F0 55 AA 52 08 02
				15 00 00 40 00 00 02 CC 30
				15 00 00 00 0D 00 02 CE 01
				15 00 00 00 00 00 02 CC 00
				/* RND Setting for LHBM */
				39 00 00 40 00 00 06 F0 55 AA 52 08 07
				15 00 00 40 00 00 02 C0 B1
				/* local hbm setting */
				39 00 00 40 00 00 06 F0 55 AA 52 08 00
				39 00 00 40 00 00 04 DF 45 00 00
				15 00 00 40 00 00 02 6F 13
				39 00 00 40 00 00 05 DF 02 D0 0B 42
				15 00 00 40 00 00 02 6F 1B
				39 00 00 40 00 00 05 DF 02 54 0A C6
				15 00 00 40 00 00 02 6F 1F
				39 00 00 40 00 00 05 DF 03 4C 0B BE
				15 00 00 40 00 00 02 6F 2B
				39 00 00 40 00 00 07 DF 3F FF 3F FF 3F FF
				15 00 00 40 00 00 02 6F 32
				39 00 00 40 00 00 07 DF 00 00 13 00 00 00
				/* EM_DT_FP-14 bit */
				15 00 00 40 00 00 02 6F 38
				39 00 00 40 00 00 03 DF 00 40
				15 00 00 40 00 00 02 6F 88
				15 00 00 40 00 00 02 DF 40
				/* FPR1_EN FPR1_CENTER_X/Y */
				15 00 00 40 00 00 02 6F 00
				39 00 00 40 00 00 06 88 01 02 D0 0B 44
				/* Dimming */
				15 00 00 40 00 00 02 53 20
				/* DBV_DIM_FP - 14 bit */
				39 00 00 40 00 00 06 F0 55 AA 52 08 00
				15 00 00 40 00 00 02 6F 4C
				39 00 00 40 00 00 03 DF 05 1C
				/* FPR Gamma code, R/G/B[11:0] */
				39 00 00 40 00 00 06 F0 55 AA 52 08 02
				39 00 00 40 00 00 07 D0 0B 06 09 97 0B 69
				/* FPR ALPHA */
				15 00 00 40 00 00 02 6F 01
				39 00 00 40 00 00 03 87 0D FF
				/* FPR ON */
				15 00 00 40 00 00 02 87 21
				15 00 00 00 00 00 02 85 00
			];
			mi,mdss-dsi-local-hbm-hlpm-white-1000nit-command-update = <0x87 49 2>, <0xD0 47 6>, <0xDF 45 2>;

			mi,mdss-dsi-local-hbm-hlpm-white-1000nit-command-state = "dsi_hs_mode";

			mi,mdss-dsi-local-hbm-hlpm-white-110nit-command = [
				/* AOD off */
				39 00 00 40 00 00 03 51 00 00
				39 00 00 40 00 00 06 F0 55 AA 52 08 01
				15 00 00 40 00 00 02 6F 02
				15 00 00 40 00 00 02 B0 08
				15 00 00 40 00 00 02 E4 80
				15 00 00 40 00 00 02 6F 0A
				15 00 00 40 00 00 02 E4 80
				15 00 00 40 00 00 02 65 00
				15 00 00 00 00 00 02 38 00
				/* restore 90hz GIR off */
				15 00 00 40 00 00 02 2F 01
				15 00 00 40 00 00 02 5F 01
				15 00 00 40 00 00 02 26 00
				15 00 00 40 00 00 02 8B 00
				39 00 00 40 00 00 06 F0 55 AA 52 08 00
				15 00 00 40 00 00 02 6F 03
				15 00 00 40 00 00 02 C0 10
				15 00 00 40 00 00 02 6F 31
				15 00 00 40 00 00 02 DF 20
				39 00 00 40 00 00 06 F0 55 AA 52 08 02
				15 00 00 40 00 00 02 CC 30
				15 00 00 00 0D 00 02 CE 01
				15 00 00 00 00 00 02 CC 00
				/* RND Setting for LHBM */
				39 00 00 40 00 00 06 F0 55 AA 52 08 07
				15 00 00 40 00 00 02 C0 B1
				/* local hbm setting */
				39 00 00 40 00 00 06 F0 55 AA 52 08 00
				39 00 00 40 00 00 04 DF 45 00 00
				15 00 00 40 00 00 02 6F 13
				39 00 00 40 00 00 05 DF 02 D0 0B 42
				15 00 00 40 00 00 02 6F 1B
				39 00 00 40 00 00 05 DF 02 54 0A C6
				15 00 00 40 00 00 02 6F 1F
				39 00 00 40 00 00 05 DF 03 4C 0B BE
				15 00 00 40 00 00 02 6F 2B
				39 00 00 40 00 00 07 DF 3F FF 3F FF 3F FF
				15 00 00 40 00 00 02 6F 32
				39 00 00 40 00 00 07 DF 00 00 13 00 00 00
				/* EM_DT_FP-14 bit */
				15 00 00 40 00 00 02 6F 38
				39 00 00 40 00 00 03 DF 00 40
				15 00 00 40 00 00 02 6F 88
				15 00 00 40 00 00 02 DF 40
				/* FPR1_EN FPR1_CENTER_X/Y */
				15 00 00 40 00 00 02 6F 00
				39 00 00 40 00 00 06 88 01 02 D0 0B 44
				/* Dimming */
				15 00 00 40 00 00 02 53 20
				/* DBV_DIM_FP - 14 bit */
				39 00 00 40 00 00 06 F0 55 AA 52 08 00
				15 00 00 40 00 00 02 6F 4C
				39 00 00 40 00 00 03 DF 05 1C
				/* FPR Gamma code, R/G/B[11:0] */
				39 00 00 40 00 00 06 F0 55 AA 52 08 02
				39 00 00 40 00 00 07 D0 08 00 07 26 08 7F
				/* FPR ALPHA */
				15 00 00 40 00 00 02 6F 01
				39 00 00 40 00 00 03 87 0D FF
				/* FPR ON */
				15 00 00 40 00 00 02 87 21
				15 00 00 00 00 00 02 85 00
			];
			mi,mdss-dsi-local-hbm-hlpm-white-110nit-command-update  = <0x87 49 3>, <0xD0 47 6>;
			mi,mdss-dsi-local-hbm-hlpm-white-110nit-command-state = "dsi_hs_mode";

			#include "dsi-panel-m11a-42-02-0a-dsc-cmd-common.dtsi"
		};

		/* 120hz */
		timing@2 {
			/* <flat on gamma, flat off gamma> */
			mi,mdss-flat-status-control-gamma-cfg = <0x32 0x10>;
			mi,mdss-flat-status-control-lhbm-gamma-cfg = <0x22 0x20>;

			mi,mdss-dsi-flat-mode-on-command = [
				15 00 00 00 00 00 02 2F 00
				15 00 00 40 00 00 02 5F 00
				15 00 00 40 00 00 02 26 02
				15 00 00 40 00 00 02 8B 00
				39 00 00 40 00 00 06 F0 55 AA 52 08 00
				15 00 00 40 00 00 02 6F 03
				15 00 00 40 00 00 02 C0 32
				15 00 00 40 00 00 02 6F 31
				15 00 00 40 00 00 02 DF 22
				39 00 00 40 00 00 06 F0 55 AA 52 08 02
				15 00 00 40 00 00 02 CC 30
				15 00 00 00 14 00 02 CE 01
			];
			mi,mdss-dsi-flat-mode-on-command-state = "dsi_lp_mode";

			mi,mdss-dsi-flat-mode-on-sec-command = [
				39 00 00 40 00 00 06 F0 55 AA 52 08 02
				15 00 00 00 00 00 02 CC 00
			];
			mi,mdss-dsi-flat-mode-on-sec-command-state = "dsi_lp_mode";

			mi,mdss-dsi-flat-mode-off-command = [
				15 00 00 00 00 00 02 2F 00
				15 00 00 40 00 00 02 5F 01
				15 00 00 40 00 00 02 26 00
				15 00 00 40 00 00 02 8B 00
				39 00 00 40 00 00 06 F0 55 AA 52 08 00
				15 00 00 40 00 00 02 6F 03
				15 00 00 40 00 00 02 C0 10
				15 00 00 40 00 00 02 6F 31
				15 00 00 40 00 00 02 DF 20
				39 00 00 40 00 00 06 F0 55 AA 52 08 02
				15 00 00 40 00 00 02 CC 30
				15 00 00 00 14 00 02 CE 01
			];
			mi,mdss-dsi-flat-mode-off-command-state = "dsi_lp_mode";

			mi,mdss-dsi-flat-mode-off-sec-command = [
				39 00 00 40 00 00 06 F0 55 AA 52 08 02
				15 00 00 00 00 00 02 CC 00
			];
			mi,mdss-dsi-flat-mode-off-sec-command-state = "dsi_lp_mode";

			mi,mdss-dsi-doze-hbm-command = [
				39 00 00 40 00 00 07 51 00 00 00 00 0F FF
				39 00 00 40 00 00 06 F0 55 AA 52 08 01
				15 00 00 40 00 00 02 6F 02
				15 00 00 40 00 00 02 B0 00
				15 00 00 40 00 00 02 E4 90
				15 00 00 40 00 00 02 6F 0A
				15 00 00 40 00 00 02 E4 90
				05 00 00 40 00 00 01 39
				15 00 00 00 00 00 02 65 01
			];
			mi,mdss-dsi-doze-hbm-command-state = "dsi_hs_mode";

			mi,mdss-dsi-doze-lbm-command = [
				39 00 00 40 00 00 07 51 00 00 00 00 01 55
				39 00 00 40 00 00 06 F0 55 AA 52 08 01
				15 00 00 40 00 00 02 6F 02
				15 00 00 40 00 00 02 B0 00
				15 00 00 40 00 00 02 E4 90
				15 00 00 40 00 00 02 6F 0A
				15 00 00 40 00 00 02 E4 90
				05 00 00 40 00 00 01 39
				15 00 00 00 00 00 02 65 01
			];
			mi,mdss-dsi-doze-lbm-command-state = "dsi_hs_mode";

			mi,mdss-dsi-doze-hbm-nolp-command = [
				39 00 00 40 00 00 06 F0 55 AA 52 08 01
				15 00 00 40 00 00 02 6F 02
				15 00 00 40 00 00 02 B0 08
				15 00 00 40 00 00 02 E4 80
				15 00 00 40 00 00 02 6F 0A
				15 00 00 40 00 00 02 E4 80
				15 00 00 40 00 00 02 65 00
				05 00 00 00 32 00 01 38
			];
			mi,mdss-dsi-doze-hbm-nolp-command-state = "dsi_hs_mode";

			mi,mdss-dsi-doze-lbm-nolp-command = [
				39 00 00 40 00 00 06 F0 55 AA 52 08 01
				15 00 00 40 00 00 02 6F 02
				15 00 00 40 00 00 02 B0 08
				15 00 00 40 00 00 02 E4 80
				15 00 00 40 00 00 02 6F 0A
				15 00 00 40 00 00 02 E4 80
				15 00 00 40 00 00 02 65 00
				05 00 00 00 32 00 01 38
			];
			mi,mdss-dsi-doze-lbm-nolp-command-state = "dsi_hs_mode";

			mi,mdss-dsi-local-hbm-off-to-hlpm-command = [
				/* Lhbm off */
				39 00 00 40 00 00 03 51 07 FF
				39 00 00 40 00 00 02 86 00
				39 00 00 00 00 00 02 87 20
				/* Aod hlpm */
				39 00 00 40 00 00 07 51 00 00 00 00 0F FF
				39 00 00 40 00 00 06 F0 55 AA 52 08 01
				39 00 00 40 00 00 02 6F 02
				39 00 00 40 00 00 02 B0 00
				39 00 00 40 00 00 02 E4 90
				39 00 00 40 00 00 02 6F 0A
				39 00 00 40 00 00 02 E4 90
				39 00 00 40 00 00 02 39 00
				39 00 00 00 00 00 02 65 01
			];
			mi,mdss-dsi-local-hbm-off-to-hlpm-command-state = "dsi_hs_mode";

			mi,mdss-dsi-local-hbm-off-to-llpm-command = [
				/* Lhbm off */
				39 00 00 40 00 00 03 51 07 FF
				39 00 00 40 00 00 02 86 00
				39 00 00 00 00 00 02 87 20
				/* Aod llpm */
				39 00 00 40 00 00 07 51 00 00 00 00 01 55
				39 00 00 40 00 00 06 F0 55 AA 52 08 01
				39 00 00 40 00 00 02 6F 02
				39 00 00 40 00 00 02 B0 00
				39 00 00 40 00 00 02 E4 90
				39 00 00 40 00 00 02 6F 0A
				39 00 00 40 00 00 02 E4 90
				39 00 00 40 00 00 02 39 00
				39 00 00 00 00 00 02 65 01
			];
			mi,mdss-dsi-local-hbm-off-to-llpm-command-state = "dsi_hs_mode";

			mi,mdss-dsi-local-hbm-hlpm-white-1000nit-command = [
				/* Aod off */
				39 00 00 40 00 00 03 51 00 00
				39 00 00 40 00 00 06 F0 55 AA 52 08 01
				15 00 00 40 00 00 02 6F 02
				15 00 00 40 00 00 02 B0 08
				15 00 00 40 00 00 02 E4 80
				15 00 00 40 00 00 02 6F 0A
				15 00 00 40 00 00 02 E4 80
				15 00 00 40 00 00 02 65 00
				15 00 00 00 00 00 02 38 00
				/* RND Setting for LHBM */
				39 00 00 40 00 00 06 F0 55 AA 52 08 07
				15 00 00 40 00 00 02 C0 B1
				/* local hbm setting */
				39 00 00 40 00 00 06 F0 55 AA 52 08 00
				39 00 00 40 00 00 04 DF 45 00 00
				15 00 00 40 00 00 02 6F 13
				39 00 00 40 00 00 05 DF 02 D0 0B 42
				15 00 00 40 00 00 02 6F 1B
				39 00 00 40 00 00 05 DF 02 54 0A C6
				15 00 00 40 00 00 02 6F 1F
				39 00 00 40 00 00 05 DF 03 4C 0B BE
				15 00 00 40 00 00 02 6F 2B
				39 00 00 40 00 00 07 DF 3F FF 3F FF 3F FF
				15 00 00 40 00 00 02 6F 32
				39 00 00 40 00 00 07 DF 00 00 13 00 00 00
				/* EM_DT_FP-14 bit */
				15 00 00 40 00 00 02 6F 38
				39 00 00 40 00 00 03 DF 00 40
				15 00 00 40 00 00 02 6F 88
				15 00 00 40 00 00 02 DF 40
				/* FPR1_EN FPR1_CENTER_X/Y */
				15 00 00 40 00 00 02 6F 00
				39 00 00 40 00 00 06 88 01 02 D0 0B 44
				/* Dimming */
				15 00 00 40 00 00 02 53 20
				/* DBV_DIM_FP - 14 bit */
				39 00 00 40 00 00 06 F0 55 AA 52 08 00
				15 00 00 40 00 00 02 6F 4C
				39 00 00 40 00 00 03 DF 05 1C
				/* FPR Gamma code, R/G/B[11:0] */
				39 00 00 40 00 00 06 F0 55 AA 52 08 02
				39 00 00 40 00 00 07 D0 0B 06 09 97 0B 69
				/* FPR ALPHA */
				15 00 00 40 00 00 02 6F 01
				39 00 00 40 00 00 03 87 0D FF
				/* FPR ON */
				15 00 00 40 00 00 02 87 21
				15 00 00 00 00 00 02 85 00
			];
			mi,mdss-dsi-local-hbm-hlpm-white-1000nit-command-update = <0x87 36 2>, <0xD0 34 6>, <0xDF 32 2>;
			mi,mdss-dsi-local-hbm-hlpm-white-1000nit-command-state = "dsi_hs_mode";

			mi,mdss-dsi-local-hbm-hlpm-white-110nit-command = [
				/* AOD off */
				39 00 00 40 00 00 03 51 00 00
				39 00 00 40 00 00 06 F0 55 AA 52 08 01
				15 00 00 40 00 00 02 6F 02
				15 00 00 40 00 00 02 B0 08
				15 00 00 40 00 00 02 E4 80
				15 00 00 40 00 00 02 6F 0A
				15 00 00 40 00 00 02 E4 80
				15 00 00 40 00 00 02 65 00
				15 00 00 00 00 00 02 38 00
				/* RND Setting for LHBM */
				39 00 00 40 00 00 06 F0 55 AA 52 08 07
				15 00 00 40 00 00 02 C0 B1
				/* local hbm setting */
				39 00 00 40 00 00 06 F0 55 AA 52 08 00
				39 00 00 40 00 00 04 DF 45 00 00
				15 00 00 40 00 00 02 6F 13
				39 00 00 40 00 00 05 DF 02 D0 0B 42
				15 00 00 40 00 00 02 6F 1B
				39 00 00 40 00 00 05 DF 02 54 0A C6
				15 00 00 40 00 00 02 6F 1F
				39 00 00 40 00 00 05 DF 03 4C 0B BE
				15 00 00 40 00 00 02 6F 2B
				39 00 00 40 00 00 07 DF 3F FF 3F FF 3F FF
				15 00 00 40 00 00 02 6F 32
				39 00 00 40 00 00 07 DF 00 00 13 00 00 00
				/* EM_DT_FP-14 bit */
				15 00 00 40 00 00 02 6F 38
				39 00 00 40 00 00 03 DF 00 40
				15 00 00 40 00 00 02 6F 88
				15 00 00 40 00 00 02 DF 40
				/* FPR1_EN FPR1_CENTER_X/Y */
				15 00 00 40 00 00 02 6F 00
				39 00 00 40 00 00 06 88 01 02 D0 0B 44
				/* Dimming */
				15 00 00 40 00 00 02 53 20
				/* DBV_DIM_FP - 14 bit */
				39 00 00 40 00 00 06 F0 55 AA 52 08 00
				15 00 00 40 00 00 02 6F 4C
				39 00 00 40 00 00 03 DF 05 1C
				/* FPR Gamma code, R/G/B[11:0] */
				39 00 00 40 00 00 06 F0 55 AA 52 08 02
				39 00 00 40 00 00 07 D0 08 00 07 26 08 7F
				/* FPR ALPHA */
				15 00 00 40 00 00 02 6F 01
				39 00 00 40 00 00 03 87 0D FF
				/* FPR ON */
				15 00 00 40 00 00 02 87 21
				15 00 00 00 00 00 02 85 00
			];
			mi,mdss-dsi-local-hbm-hlpm-white-110nit-command-update  = <0x87 36 3>, <0xD0 34 6>;
			mi,mdss-dsi-local-hbm-hlpm-white-110nit-command-state = "dsi_hs_mode";

			#include "dsi-panel-m11a-42-02-0a-dsc-cmd-common.dtsi"
		};
	};
};
